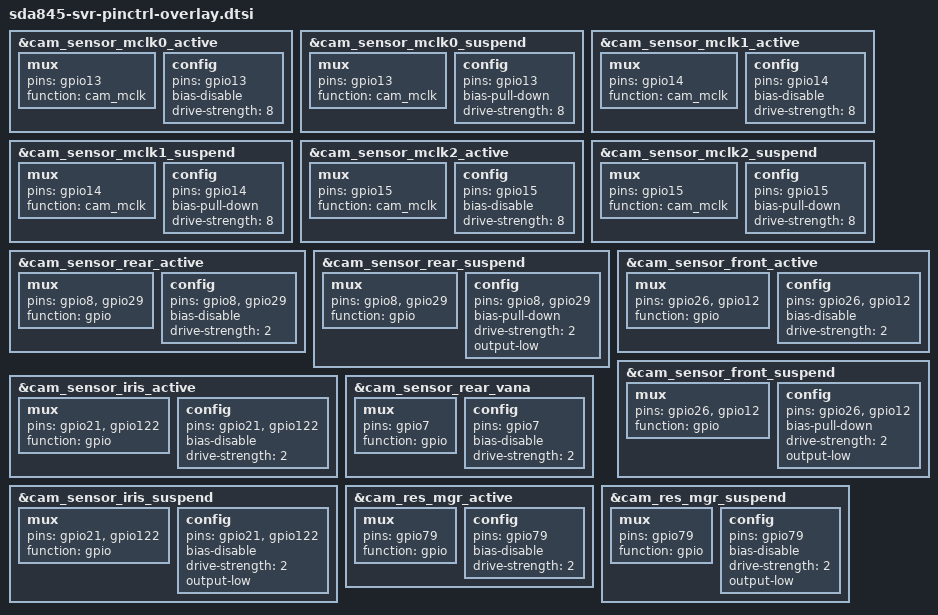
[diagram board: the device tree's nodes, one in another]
/* Copyright (c) 2018, The Linux Foundation. All rights reserved.
 *
 * This program is free software; you can redistribute it and/or modify
 * it under the terms of the GNU General Public License version 2 and
 * only version 2 as published by the Free Software Foundation.
 *
 * This program is distributed in the hope that it will be useful,
 * but WITHOUT ANY WARRANTY; without even the implied warranty of
 * MERCHANTABILITY or FITNESS FOR A PARTICULAR PURPOSE.  See the
 * GNU General Public License for more details.
 */

&cam_sensor_mclk0_active {
	/* MCLK0 */
	mux {
		pins = "gpio13";
		function = "cam_mclk";
	};

	config {
		pins = "gpio13";
		bias-disable; /* No PULL */
		drive-strength = <8>; /* 8 MA */
	};
};

&cam_sensor_mclk0_suspend {
	/* MCLK0 */
	mux {
		pins = "gpio13";
		function = "cam_mclk";
	};

	config {
		pins = "gpio13";
		bias-pull-down; /* PULL DOWN */
		drive-strength = <8>; /* 8 MA */
	};
};

&cam_sensor_mclk1_active {
	/* MCLK1 */
	mux {
		pins = "gpio14";
		function = "cam_mclk";
	};

	config {
		pins = "gpio14";
		bias-disable; /* No PULL */
		drive-strength = <8>; /* 8 MA */
	};
};

&cam_sensor_mclk1_suspend {
	/* MCLK1 */
	mux {
		pins = "gpio14";
		function = "cam_mclk";
	};

	config {
		pins = "gpio14";
		bias-pull-down; /* PULL DOWN */
		drive-strength = <8>; /* 8 MA */
	};
};

&cam_sensor_mclk2_active {
	/* MCLK2 */
	mux {
		pins = "gpio15";
		function = "cam_mclk";
	};

	config {
		pins = "gpio15";
		bias-disable; /* No PULL */
		drive-strength = <8>; /* 8 MA */
	};
};

&cam_sensor_mclk2_suspend {
	/* MCLK2 */
	mux {
		pins = "gpio15";
		function = "cam_mclk";
	};

	config {
		pins = "gpio15";
		bias-pull-down; /* PULL DOWN */
		drive-strength = <8>; /* 8 MA */
	};
};

&cam_sensor_rear_active {
	/* RESET, AVDD LDO */
	mux {
		pins = "gpio8", "gpio29";
		function = "gpio";
	};

	config {
		pins = "gpio8", "gpio29";
		bias-disable; /* No PULL */
		drive-strength = <2>; /* 2 MA */
	};
};

&cam_sensor_rear_suspend {
	/* RESET, AVDD LDO */
	mux {
		pins = "gpio8", "gpio29";
		function = "gpio";
	};

	config {
		pins = "gpio8", "gpio29";
		bias-pull-down; /* PULL DOWN */
		drive-strength = <2>; /* 2 MA */
		output-low;
	};
};

&cam_sensor_front_active {
	/* RESET  AVDD_LDO */
	mux {
		pins = "gpio26", "gpio12";
		function = "gpio";
	};

	config {
		pins = "gpio26", "gpio12";
		bias-disable; /* No PULL */
		drive-strength = <2>; /* 2 MA */
	};
};

&cam_sensor_front_suspend {
	/* RESET */
	mux {
		pins = "gpio26", "gpio12";
		function = "gpio";
	};

	config {
		pins = "gpio26", "gpio12";
		bias-pull-down; /* PULL DOWN */
		drive-strength = <2>; /* 2 MA */
		output-low;
	};
};

&cam_sensor_iris_active {
	/* RESET  AVDD_LDO */
	mux {
		pins = "gpio21", "gpio122";
		function = "gpio";
	};

	config {
		pins = "gpio21", "gpio122";
		bias-disable; /* No PULL */
		drive-strength = <2>; /* 2 MA */
	};
};

&cam_sensor_iris_suspend {
	/* RESET  AVDD_LDO */
	mux {
		pins = "gpio21", "gpio122";
		function = "gpio";
	};

	config {
		pins = "gpio21", "gpio122";
		bias-disable; /* No PULL */
		drive-strength = <2>; /* 2 MA */
		output-low;
	};
};

&cam_sensor_rear_vana {
	/* AVDD_LDO */
	mux {
		pins = "gpio7";
		function = "gpio";
	};

	config {
		pins = "gpio7";
		bias-disable; /* No PULL */
		drive-strength = <2>; /* 2 MA */
	};
};

&cam_res_mgr_active {
	/* AVDD_LDO */
	mux {
		pins = "gpio79";
		function = "gpio";
	};

	config {
		pins = "gpio79";
		bias-disable; /* No PULL */
		drive-strength = <2>; /* 2 MA */
	};
};

&cam_res_mgr_suspend {
	/* AVDD_LDO */
	mux {
		pins = "gpio79";
		function = "gpio";
	};

	config {
		pins = "gpio79";
		bias-disable; /* No PULL */
		drive-strength = <2>; /* 2 MA */
		output-low;
	};
};
